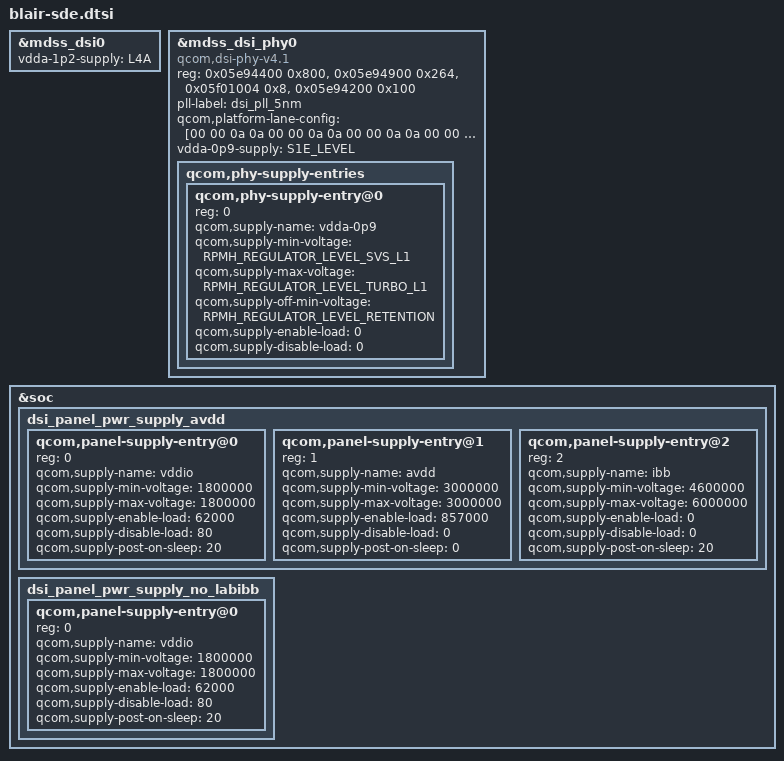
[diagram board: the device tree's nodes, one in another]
#include "holi-sde.dtsi"

&mdss_dsi0 {
	vdda-1p2-supply = <&L4A>;
};

&mdss_dsi_phy0 {
	compatible = "qcom,dsi-phy-v4.1";
	reg = <0x05e94400 0x800>,
	      <0x05e94900 0x264>,
	      <0x05f01004 0x8>,
	      <0x05e94200 0x100>;
	reg-names = "dsi_phy", "pll_base", "gdsc_base", "dyn_refresh_base";
	pll-label = "dsi_pll_5nm";

	qcom,platform-lane-config = [00 00 0a 0a
				     00 00 0a 0a
				     00 00 0a 0a
				     00 00 0a 0a
				     00 00 8a 8a];

	vdda-0p9-supply = <&S1E_LEVEL>;
	qcom,phy-supply-entries {
		#address-cells = <1>;
		#size-cells = <0>;
		qcom,phy-supply-entry@0 {
			reg = <0>;
			qcom,supply-name = "vdda-0p9";
			qcom,supply-min-voltage =
				<RPMH_REGULATOR_LEVEL_SVS_L1>;
			qcom,supply-max-voltage =
				<RPMH_REGULATOR_LEVEL_TURBO_L1>;
			qcom,supply-off-min-voltage =
				<RPMH_REGULATOR_LEVEL_RETENTION>;
			qcom,supply-enable-load = <0>;
			qcom,supply-disable-load = <0>;
		};
	};
};

&soc {
	dsi_panel_pwr_supply_avdd: dsi_panel_pwr_supply_avdd {
		#size-cells = <0>;
		#address-cells = <1>;

		qcom,panel-supply-entry@0 {
			reg = <0>;
			qcom,supply-name = "vddio";
			qcom,supply-min-voltage = <1800000>;
			qcom,supply-max-voltage = <1800000>;
			qcom,supply-enable-load = <62000>;
			qcom,supply-disable-load = <80>;
			qcom,supply-post-on-sleep = <20>;
		};

		qcom,panel-supply-entry@1 {
			reg = <1>;
			qcom,supply-name = "avdd";
			qcom,supply-min-voltage = <3000000>;
			qcom,supply-max-voltage = <3000000>;
			qcom,supply-enable-load = <857000>;
			qcom,supply-disable-load = <0>;
			qcom,supply-post-on-sleep = <0>;
		};

		qcom,panel-supply-entry@2 {
			reg = <2>;
			qcom,supply-name = "ibb";
			qcom,supply-min-voltage = <4600000>;
			qcom,supply-max-voltage = <6000000>;
			qcom,supply-enable-load = <0>;
			qcom,supply-disable-load = <0>;
			qcom,supply-post-on-sleep = <20>;
		};
	};

	dsi_panel_pwr_supply_no_labibb: dsi_panel_pwr_supply_no_labibb {
		#size-cells = <0>;
		#address-cells = <1>;

		qcom,panel-supply-entry@0 {
			reg = <0>;
			qcom,supply-name = "vddio";
			qcom,supply-min-voltage = <1800000>;
			qcom,supply-max-voltage = <1800000>;
			qcom,supply-enable-load = <62000>;
			qcom,supply-disable-load = <80>;
			qcom,supply-post-on-sleep = <20>;
		};
	};
};

